# VPAC0_COMMON_0_PAR_VPAC_VISS0_S_VBUSP_VISS_RAWFE_CFG_MMR_S_VBUSP_RAWFE_CFG register map
Vendor: Texas Instruments
Peripheral module from a debugger description file (folder J721S2).
Registers are 32-bit, read-write, reset 0x0 unless marked. A register's access mark holds for its fields unless they carry their own. Offsets are as the file gives them; lines under a group give offsets from that group; [hi:lo] are bit positions; {n}, {i} and the like mark numbered series; 'fields as' and 'values as' point back to an identical list; <NAME> marks a mode.

## VPAC0_COMMON_0_PAR_VPAC_VISS0_S_VBUSP_VISS_RAWFE_CFG_MMR_S_VBUSP_RAWFE_CFG
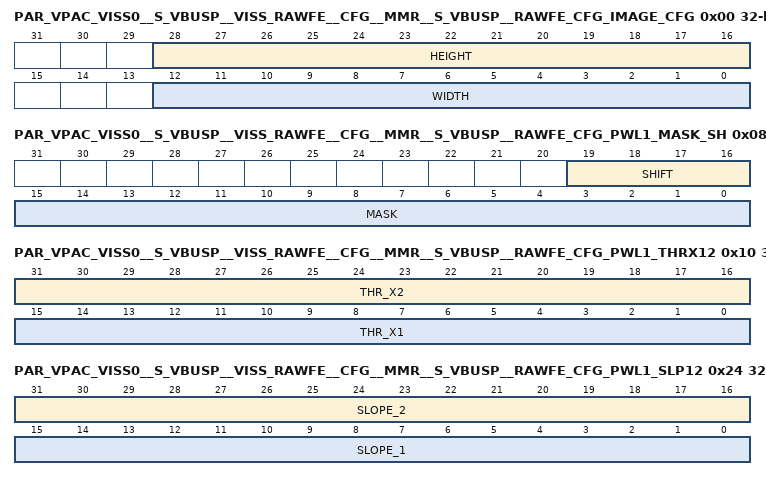
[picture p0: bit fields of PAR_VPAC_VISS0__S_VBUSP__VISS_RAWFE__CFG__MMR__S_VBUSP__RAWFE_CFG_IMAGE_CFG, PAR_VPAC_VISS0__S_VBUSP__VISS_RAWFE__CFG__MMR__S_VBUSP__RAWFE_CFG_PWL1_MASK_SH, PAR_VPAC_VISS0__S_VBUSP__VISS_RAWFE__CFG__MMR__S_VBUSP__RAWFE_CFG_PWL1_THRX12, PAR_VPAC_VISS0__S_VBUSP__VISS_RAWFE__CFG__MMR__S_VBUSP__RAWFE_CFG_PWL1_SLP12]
0x00 PAR_VPAC_VISS0__S_VBUSP__VISS_RAWFE__CFG__MMR__S_VBUSP__RAWFE_CFG_IMAGE_CFG
  [28:16] HEIGHT — image height
  [12:0] WIDTH — image width
0x04 PAR_VPAC_VISS0__S_VBUSP__VISS_RAWFE__CFG__MMR__S_VBUSP__RAWFE_CFG_SHADOW_CFG
  [0] LUT3_SHDW_EN — use LUT2 ram as LUT table for LUT3 processing
0x08 PAR_VPAC_VISS0__S_VBUSP__VISS_RAWFE__CFG__MMR__S_VBUSP__RAWFE_CFG_PWL1_MASK_SH
  [19:16] SHIFT — number of right shift
  [15:0] MASK — mask bit pattern
0x0C PAR_VPAC_VISS0__S_VBUSP__VISS_RAWFE__CFG__MMR__S_VBUSP__RAWFE_CFG_PWL1_EN
  [0] ENABLE
0x10 PAR_VPAC_VISS0__S_VBUSP__VISS_RAWFE__CFG__MMR__S_VBUSP__RAWFE_CFG_PWL1_THRX12
  [31:16] THR_X2 — threshold X2
  [15:0] THR_X1 — threshold X1
0x14 PAR_VPAC_VISS0__S_VBUSP__VISS_RAWFE__CFG__MMR__S_VBUSP__RAWFE_CFG_PWL1_THRX3
  [15:0] THR_X3 — threshold X3
{0x14+4i} PAR_VPAC_VISS0__S_VBUSP__VISS_RAWFE__CFG__MMR__S_VBUSP__RAWFE_CFG_PWL1_THRY{i} (i=1..3)
  [23:0] THR_Y{i} — threshold Y{i}
0x24 PAR_VPAC_VISS0__S_VBUSP__VISS_RAWFE__CFG__MMR__S_VBUSP__RAWFE_CFG_PWL1_SLP12
  [31:16] SLOPE_2, [15:0] SLOPE_1
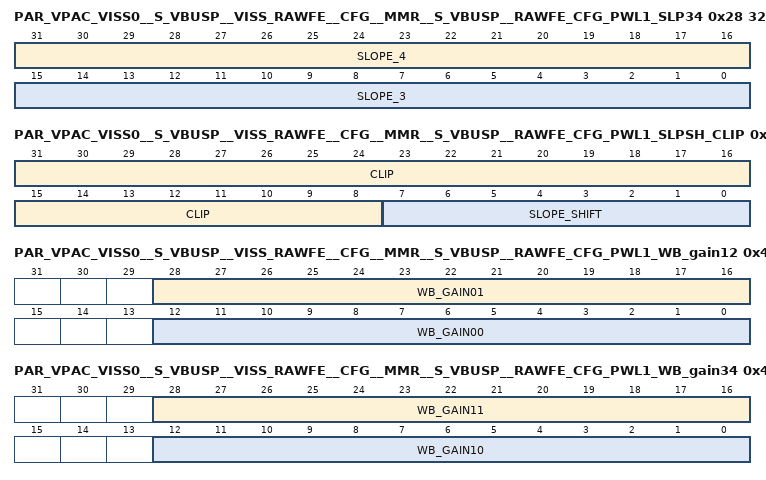
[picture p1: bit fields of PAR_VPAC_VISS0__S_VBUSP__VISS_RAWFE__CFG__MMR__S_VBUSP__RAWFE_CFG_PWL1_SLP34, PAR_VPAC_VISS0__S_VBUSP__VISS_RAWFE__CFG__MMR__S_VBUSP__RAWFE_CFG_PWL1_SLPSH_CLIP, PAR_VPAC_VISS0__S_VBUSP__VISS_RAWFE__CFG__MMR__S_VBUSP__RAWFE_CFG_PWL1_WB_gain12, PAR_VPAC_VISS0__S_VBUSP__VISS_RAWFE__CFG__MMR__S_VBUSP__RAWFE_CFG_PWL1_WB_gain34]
0x28 PAR_VPAC_VISS0__S_VBUSP__VISS_RAWFE__CFG__MMR__S_VBUSP__RAWFE_CFG_PWL1_SLP34
  [31:16] SLOPE_4, [15:0] SLOPE_3
0x2C PAR_VPAC_VISS0__S_VBUSP__VISS_RAWFE__CFG__MMR__S_VBUSP__RAWFE_CFG_PWL1_SLPSH_CLIP
  [31:8] CLIP — clip value
  [7:0] SLOPE_SHIFT — shift value for slope, must not exceed decimal 33.
0x30 PAR_VPAC_VISS0__S_VBUSP__VISS_RAWFE__CFG__MMR__S_VBUSP__RAWFE_CFG_PWL1_OFF1 access not given
  [23:0] OFST00 rw — S24, Offset at pixel 00
0x34 PAR_VPAC_VISS0__S_VBUSP__VISS_RAWFE__CFG__MMR__S_VBUSP__RAWFE_CFG_PWL1_OFF2 access not given
  [23:0] OFST01 rw — S24, Offset at pixel 01
0x38 PAR_VPAC_VISS0__S_VBUSP__VISS_RAWFE__CFG__MMR__S_VBUSP__RAWFE_CFG_PWL1_OFF3 access not given
  [23:0] OFST10 rw — S24, Offset at pixel 10
0x3C PAR_VPAC_VISS0__S_VBUSP__VISS_RAWFE__CFG__MMR__S_VBUSP__RAWFE_CFG_PWL1_OFF4 access not given
  [23:0] OFST11 rw — S24, Offset at pixel 11
0x40 PAR_VPAC_VISS0__S_VBUSP__VISS_RAWFE__CFG__MMR__S_VBUSP__RAWFE_CFG_PWL1_WB_gain12
  [28:16] WB_GAIN01 — U13Q9, WB gain at pixel 01
  [12:0] WB_GAIN00 — U13Q9, WB gain at pixel 00
0x44 PAR_VPAC_VISS0__S_VBUSP__VISS_RAWFE__CFG__MMR__S_VBUSP__RAWFE_CFG_PWL1_WB_gain34
  [28:16] WB_GAIN11 — U13Q9, WB gain at pixel 11
  [12:0] WB_GAIN10 — U13Q9, WB gain at pixel 10
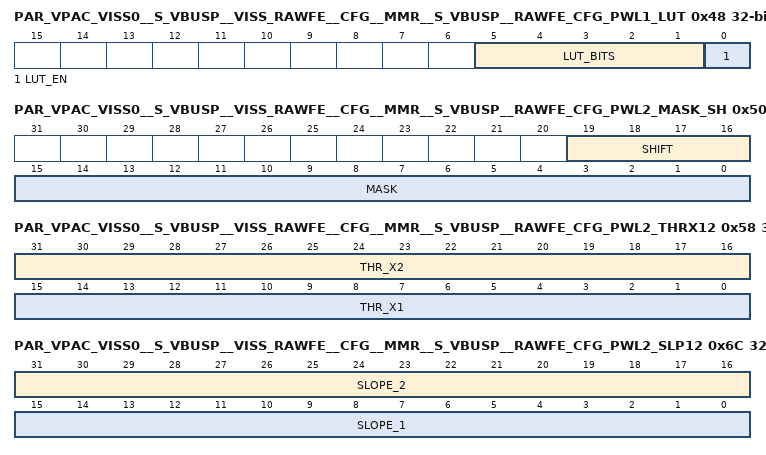
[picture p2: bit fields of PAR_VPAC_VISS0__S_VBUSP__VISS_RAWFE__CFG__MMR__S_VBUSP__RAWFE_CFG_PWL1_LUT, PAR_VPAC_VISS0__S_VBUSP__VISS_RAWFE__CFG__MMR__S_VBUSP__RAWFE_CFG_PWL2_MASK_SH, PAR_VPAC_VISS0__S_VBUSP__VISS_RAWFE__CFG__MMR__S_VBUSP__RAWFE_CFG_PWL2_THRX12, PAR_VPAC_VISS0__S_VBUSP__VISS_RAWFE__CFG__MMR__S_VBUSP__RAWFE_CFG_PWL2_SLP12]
0x48 PAR_VPAC_VISS0__S_VBUSP__VISS_RAWFE__CFG__MMR__S_VBUSP__RAWFE_CFG_PWL1_LUT
  [5:1] LUT_BITS — LUT input bit depth, up to 24
  [0] LUT_EN — enable LUT based compression
0x4C PAR_VPAC_VISS0__S_VBUSP__VISS_RAWFE__CFG__MMR__S_VBUSP__RAWFE_CFG_PWL1_LUTCLIP
  [15:0] LUTCLIP — LUT clip value
0x50 PAR_VPAC_VISS0__S_VBUSP__VISS_RAWFE__CFG__MMR__S_VBUSP__RAWFE_CFG_PWL2_MASK_SH
  fields as PAR_VPAC_VISS0__S_VBUSP__VISS_RAWFE__CFG__MMR__S_VBUSP__RAWFE_CFG_PWL1_MASK_SH
0x54 PAR_VPAC_VISS0__S_VBUSP__VISS_RAWFE__CFG__MMR__S_VBUSP__RAWFE_CFG_PWL2_EN
  [0] ENABLE
0x58 PAR_VPAC_VISS0__S_VBUSP__VISS_RAWFE__CFG__MMR__S_VBUSP__RAWFE_CFG_PWL2_THRX12
  [31:16] THR_X2 — threshold X2
  [15:0] THR_X1 — threshold X1
0x5C PAR_VPAC_VISS0__S_VBUSP__VISS_RAWFE__CFG__MMR__S_VBUSP__RAWFE_CFG_PWL2_THRX3
  [15:0] THR_X3 — threshold X3
{0x5C+4i} PAR_VPAC_VISS0__S_VBUSP__VISS_RAWFE__CFG__MMR__S_VBUSP__RAWFE_CFG_PWL2_THRY{i} (i=1..3)
  [23:0] THR_Y{i} — threshold Y{i}
0x6C PAR_VPAC_VISS0__S_VBUSP__VISS_RAWFE__CFG__MMR__S_VBUSP__RAWFE_CFG_PWL2_SLP12
  [31:16] SLOPE_2, [15:0] SLOPE_1
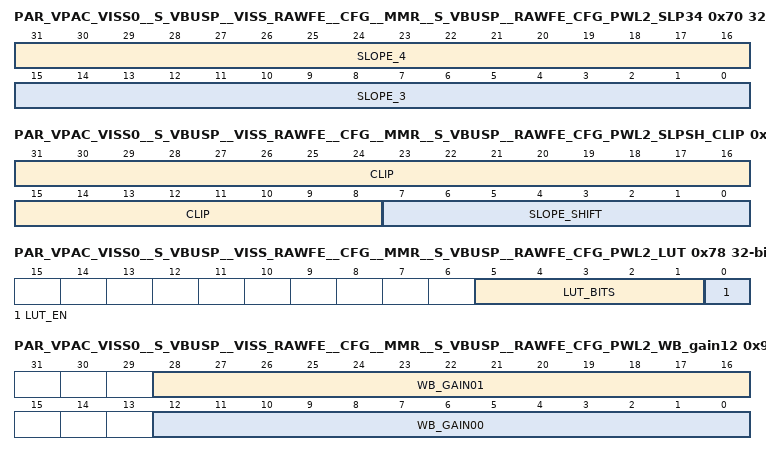
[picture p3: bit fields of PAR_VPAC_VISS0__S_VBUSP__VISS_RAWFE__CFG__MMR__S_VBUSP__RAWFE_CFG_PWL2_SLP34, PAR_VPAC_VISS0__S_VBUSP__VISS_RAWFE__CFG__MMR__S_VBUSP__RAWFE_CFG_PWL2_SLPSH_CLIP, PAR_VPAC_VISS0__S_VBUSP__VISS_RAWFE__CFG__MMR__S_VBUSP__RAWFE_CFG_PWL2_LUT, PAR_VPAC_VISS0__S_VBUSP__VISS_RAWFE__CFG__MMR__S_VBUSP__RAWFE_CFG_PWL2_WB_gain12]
0x70 PAR_VPAC_VISS0__S_VBUSP__VISS_RAWFE__CFG__MMR__S_VBUSP__RAWFE_CFG_PWL2_SLP34
  [31:16] SLOPE_4, [15:0] SLOPE_3
0x74 PAR_VPAC_VISS0__S_VBUSP__VISS_RAWFE__CFG__MMR__S_VBUSP__RAWFE_CFG_PWL2_SLPSH_CLIP
  [31:8] CLIP — clip value
  [7:0] SLOPE_SHIFT — shift value for slope, must not exceed decimal 33
0x78 PAR_VPAC_VISS0__S_VBUSP__VISS_RAWFE__CFG__MMR__S_VBUSP__RAWFE_CFG_PWL2_LUT
  fields as PAR_VPAC_VISS0__S_VBUSP__VISS_RAWFE__CFG__MMR__S_VBUSP__RAWFE_CFG_PWL1_LUT
0x7C PAR_VPAC_VISS0__S_VBUSP__VISS_RAWFE__CFG__MMR__S_VBUSP__RAWFE_CFG_PWL2_LUTCLIP
  [15:0] LUTCLIP — LUT clip value
0x80 PAR_VPAC_VISS0__S_VBUSP__VISS_RAWFE__CFG__MMR__S_VBUSP__RAWFE_CFG_PWL2_OFF1 access not given
  [23:0] OFST00 rw — S24, WB Offset at pixel 00
0x84 PAR_VPAC_VISS0__S_VBUSP__VISS_RAWFE__CFG__MMR__S_VBUSP__RAWFE_CFG_PWL2_OFF2 access not given
  [23:0] OFST01 rw — S24, Offset at pixel 01
0x88 PAR_VPAC_VISS0__S_VBUSP__VISS_RAWFE__CFG__MMR__S_VBUSP__RAWFE_CFG_PWL2_OFF3 access not given
  [23:0] OFST10 rw — S24, Offset at pixel 10
0x8C PAR_VPAC_VISS0__S_VBUSP__VISS_RAWFE__CFG__MMR__S_VBUSP__RAWFE_CFG_PWL2_OFF4 access not given
  [23:0] OFST11 rw — S24, Offset at pixel 11
0x90 PAR_VPAC_VISS0__S_VBUSP__VISS_RAWFE__CFG__MMR__S_VBUSP__RAWFE_CFG_PWL2_WB_gain12
  fields as PAR_VPAC_VISS0__S_VBUSP__VISS_RAWFE__CFG__MMR__S_VBUSP__RAWFE_CFG_PWL1_WB_gain12
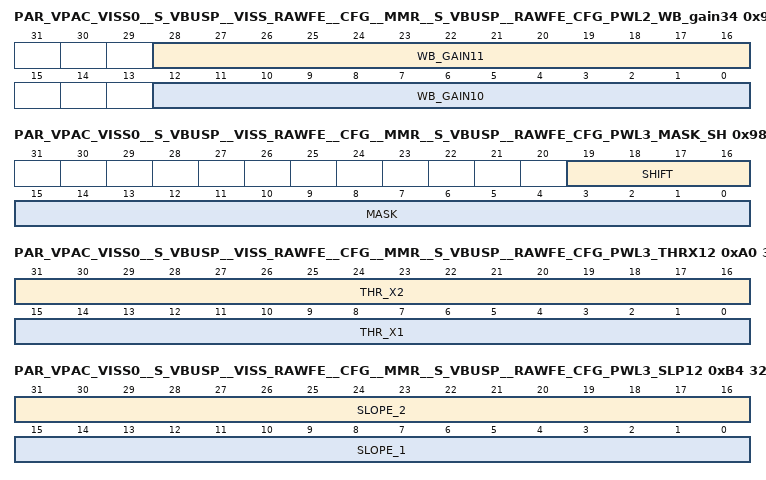
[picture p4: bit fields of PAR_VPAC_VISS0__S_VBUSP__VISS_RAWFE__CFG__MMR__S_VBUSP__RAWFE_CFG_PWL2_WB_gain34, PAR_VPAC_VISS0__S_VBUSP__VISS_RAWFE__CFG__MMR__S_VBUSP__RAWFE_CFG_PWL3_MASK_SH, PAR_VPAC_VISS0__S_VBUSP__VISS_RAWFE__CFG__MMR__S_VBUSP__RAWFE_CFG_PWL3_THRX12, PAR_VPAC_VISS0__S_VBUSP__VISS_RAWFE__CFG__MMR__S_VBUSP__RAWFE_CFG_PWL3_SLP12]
0x94 PAR_VPAC_VISS0__S_VBUSP__VISS_RAWFE__CFG__MMR__S_VBUSP__RAWFE_CFG_PWL2_WB_gain34
  fields as PAR_VPAC_VISS0__S_VBUSP__VISS_RAWFE__CFG__MMR__S_VBUSP__RAWFE_CFG_PWL1_WB_gain34
0x98 PAR_VPAC_VISS0__S_VBUSP__VISS_RAWFE__CFG__MMR__S_VBUSP__RAWFE_CFG_PWL3_MASK_SH
  fields as PAR_VPAC_VISS0__S_VBUSP__VISS_RAWFE__CFG__MMR__S_VBUSP__RAWFE_CFG_PWL1_MASK_SH
0x9C PAR_VPAC_VISS0__S_VBUSP__VISS_RAWFE__CFG__MMR__S_VBUSP__RAWFE_CFG_PWL3_EN
  [0] ENABLE
0xA0 PAR_VPAC_VISS0__S_VBUSP__VISS_RAWFE__CFG__MMR__S_VBUSP__RAWFE_CFG_PWL3_THRX12
  [31:16] THR_X2 — threshold X2
  [15:0] THR_X1 — threshold X1
0xA4 PAR_VPAC_VISS0__S_VBUSP__VISS_RAWFE__CFG__MMR__S_VBUSP__RAWFE_CFG_PWL3_THRX3
  [15:0] THR_X3 — threshold X3
{0xA4+4i} PAR_VPAC_VISS0__S_VBUSP__VISS_RAWFE__CFG__MMR__S_VBUSP__RAWFE_CFG_PWL3_THRY{i} (i=1..3)
  [23:0] THR_Y{i} — threshold Y{i}
0xB4 PAR_VPAC_VISS0__S_VBUSP__VISS_RAWFE__CFG__MMR__S_VBUSP__RAWFE_CFG_PWL3_SLP12
  [31:16] SLOPE_2, [15:0] SLOPE_1
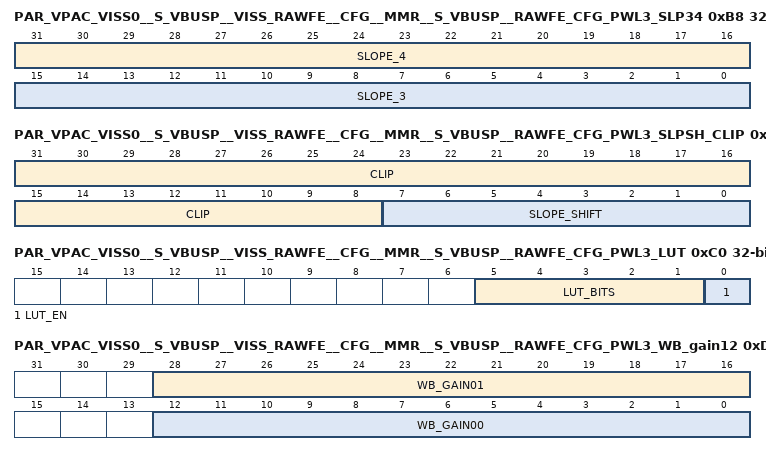
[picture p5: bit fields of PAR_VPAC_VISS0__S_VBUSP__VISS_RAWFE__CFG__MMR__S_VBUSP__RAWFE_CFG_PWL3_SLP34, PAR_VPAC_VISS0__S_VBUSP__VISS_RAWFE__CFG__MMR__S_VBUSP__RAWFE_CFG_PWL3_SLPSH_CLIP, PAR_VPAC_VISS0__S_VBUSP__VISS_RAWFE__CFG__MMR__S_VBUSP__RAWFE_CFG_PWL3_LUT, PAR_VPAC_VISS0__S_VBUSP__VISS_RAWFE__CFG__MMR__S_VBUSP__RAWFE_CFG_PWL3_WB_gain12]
0xB8 PAR_VPAC_VISS0__S_VBUSP__VISS_RAWFE__CFG__MMR__S_VBUSP__RAWFE_CFG_PWL3_SLP34
  [31:16] SLOPE_4, [15:0] SLOPE_3
0xBC PAR_VPAC_VISS0__S_VBUSP__VISS_RAWFE__CFG__MMR__S_VBUSP__RAWFE_CFG_PWL3_SLPSH_CLIP
  fields as PAR_VPAC_VISS0__S_VBUSP__VISS_RAWFE__CFG__MMR__S_VBUSP__RAWFE_CFG_PWL2_SLPSH_CLIP
0xC0 PAR_VPAC_VISS0__S_VBUSP__VISS_RAWFE__CFG__MMR__S_VBUSP__RAWFE_CFG_PWL3_LUT
  fields as PAR_VPAC_VISS0__S_VBUSP__VISS_RAWFE__CFG__MMR__S_VBUSP__RAWFE_CFG_PWL1_LUT
0xC4 PAR_VPAC_VISS0__S_VBUSP__VISS_RAWFE__CFG__MMR__S_VBUSP__RAWFE_CFG_PWL3_LUTCLIP
  [15:0] LUTCLIP — LUT clip value
0xC8 PAR_VPAC_VISS0__S_VBUSP__VISS_RAWFE__CFG__MMR__S_VBUSP__RAWFE_CFG_PWL3_OFF1 access not given
  [23:0] OFST00 rw — S24, Offset at pixel 00
0xCC PAR_VPAC_VISS0__S_VBUSP__VISS_RAWFE__CFG__MMR__S_VBUSP__RAWFE_CFG_PWL3_OFF2 access not given
  [23:0] OFST01 rw — S24, Offset at pixel 01
0xD0 PAR_VPAC_VISS0__S_VBUSP__VISS_RAWFE__CFG__MMR__S_VBUSP__RAWFE_CFG_PWL3_OFF3 access not given
  [23:0] OFST10 rw — S24, Offset at pixel 10
0xD4 PAR_VPAC_VISS0__S_VBUSP__VISS_RAWFE__CFG__MMR__S_VBUSP__RAWFE_CFG_PWL3_OFF4 access not given
  [23:0] OFST11 rw — S24, Offset at pixel 11
0xD8 PAR_VPAC_VISS0__S_VBUSP__VISS_RAWFE__CFG__MMR__S_VBUSP__RAWFE_CFG_PWL3_WB_gain12
  fields as PAR_VPAC_VISS0__S_VBUSP__VISS_RAWFE__CFG__MMR__S_VBUSP__RAWFE_CFG_PWL1_WB_gain12
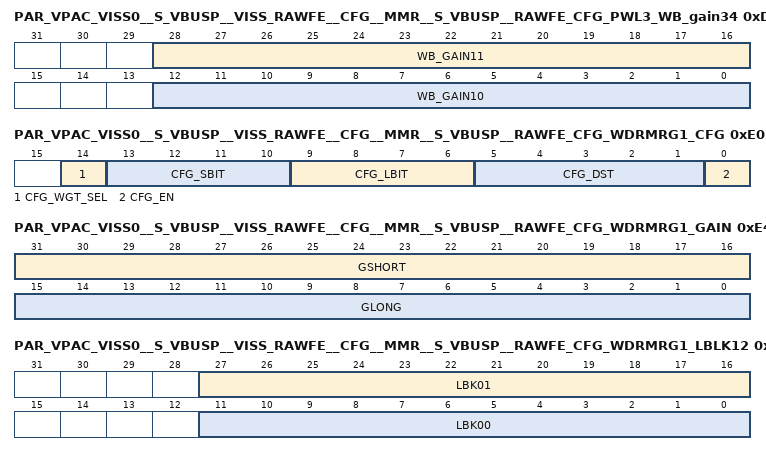
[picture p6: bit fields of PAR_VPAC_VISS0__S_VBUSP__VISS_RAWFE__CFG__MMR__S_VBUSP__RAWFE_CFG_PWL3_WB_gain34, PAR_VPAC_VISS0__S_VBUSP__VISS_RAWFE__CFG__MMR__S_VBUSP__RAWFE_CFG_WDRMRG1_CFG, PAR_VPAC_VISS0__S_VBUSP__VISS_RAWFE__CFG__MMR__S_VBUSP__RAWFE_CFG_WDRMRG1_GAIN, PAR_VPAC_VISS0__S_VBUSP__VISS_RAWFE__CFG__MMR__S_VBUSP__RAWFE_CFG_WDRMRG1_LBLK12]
0xDC PAR_VPAC_VISS0__S_VBUSP__VISS_RAWFE__CFG__MMR__S_VBUSP__RAWFE_CFG_PWL3_WB_gain34
  fields as PAR_VPAC_VISS0__S_VBUSP__VISS_RAWFE__CFG__MMR__S_VBUSP__RAWFE_CFG_PWL1_WB_gain34
0xE0 PAR_VPAC_VISS0__S_VBUSP__VISS_RAWFE__CFG__MMR__S_VBUSP__RAWFE_CFG_WDRMRG1_CFG
  [14] CFG_WGT_SEL — Select source for weight calculation (0:long, 1: short)
  [13:10] CFG_SBIT — U4, short exposure image bit shift
  [9:6] CFG_LBIT — U4, long exposure image bit shift
  [5:1] CFG_DST — U5, down shift value after WDR merge
  [0] CFG_EN — enable
0xE4 PAR_VPAC_VISS0__S_VBUSP__VISS_RAWFE__CFG__MMR__S_VBUSP__RAWFE_CFG_WDRMRG1_GAIN
  [31:16] GSHORT — U16Q15, gain for long frame
  [15:0] GLONG — U16Q15, gain for short frame
0xE8 PAR_VPAC_VISS0__S_VBUSP__VISS_RAWFE__CFG__MMR__S_VBUSP__RAWFE_CFG_WDRMRG1_LBLK12
  [27:16] LBK01 — U12, black level for long frame at pixel 01
  [11:0] LBK00 — U12, black level for long frame at pixel 00
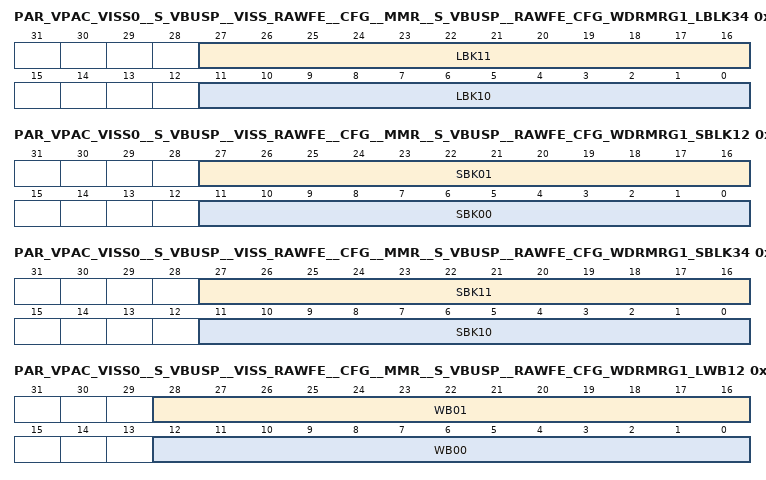
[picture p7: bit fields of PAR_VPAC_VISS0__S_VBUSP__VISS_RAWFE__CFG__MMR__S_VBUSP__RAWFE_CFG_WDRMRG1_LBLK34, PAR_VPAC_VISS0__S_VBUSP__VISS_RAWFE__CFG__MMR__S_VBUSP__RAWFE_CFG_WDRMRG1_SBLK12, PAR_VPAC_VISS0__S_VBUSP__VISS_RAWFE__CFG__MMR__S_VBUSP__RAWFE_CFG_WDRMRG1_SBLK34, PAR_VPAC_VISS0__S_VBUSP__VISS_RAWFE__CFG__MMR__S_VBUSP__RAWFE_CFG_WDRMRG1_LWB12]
0xEC PAR_VPAC_VISS0__S_VBUSP__VISS_RAWFE__CFG__MMR__S_VBUSP__RAWFE_CFG_WDRMRG1_LBLK34
  [27:16] LBK11 — U12, black level for long frame at pixel 11
  [11:0] LBK10 — U12, black level for long frame at pixel 10
0xF0 PAR_VPAC_VISS0__S_VBUSP__VISS_RAWFE__CFG__MMR__S_VBUSP__RAWFE_CFG_WDRMRG1_SBLK12
  [27:16] SBK01 — U12, black level for short frame at pixel 01
  [11:0] SBK00 — U12, black level for short frame at pixel 00
0xF4 PAR_VPAC_VISS0__S_VBUSP__VISS_RAWFE__CFG__MMR__S_VBUSP__RAWFE_CFG_WDRMRG1_SBLK34
  [27:16] SBK11 — U12, black level for short frame at pixel 11
  [11:0] SBK10 — U12, black level for short frame at pixel 10
0xF8 PAR_VPAC_VISS0__S_VBUSP__VISS_RAWFE__CFG__MMR__S_VBUSP__RAWFE_CFG_WDRMRG1_LWB12
  [28:16] WB01 — U13Q9, WB gain for long frame at pixel 01
  [12:0] WB00 — U13Q9, WB gain for long frame at pixel 00
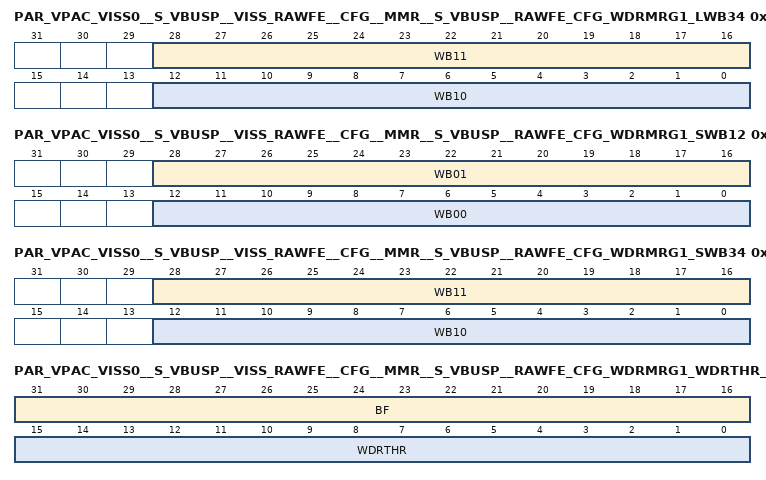
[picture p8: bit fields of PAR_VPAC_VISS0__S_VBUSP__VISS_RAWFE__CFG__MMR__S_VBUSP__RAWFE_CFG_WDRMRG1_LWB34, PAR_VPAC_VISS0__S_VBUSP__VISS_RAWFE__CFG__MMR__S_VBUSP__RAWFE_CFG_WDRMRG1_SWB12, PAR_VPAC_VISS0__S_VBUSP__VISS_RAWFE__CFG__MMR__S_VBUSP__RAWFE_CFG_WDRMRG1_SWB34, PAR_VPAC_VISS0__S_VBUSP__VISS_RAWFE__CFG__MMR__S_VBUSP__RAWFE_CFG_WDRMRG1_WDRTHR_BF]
0xFC PAR_VPAC_VISS0__S_VBUSP__VISS_RAWFE__CFG__MMR__S_VBUSP__RAWFE_CFG_WDRMRG1_LWB34
  [28:16] WB11 — U13Q9, WB gain for long frame at pixel 11
  [12:0] WB10 — U13Q9, WB gain for long frame at pixel 10
0x100 PAR_VPAC_VISS0__S_VBUSP__VISS_RAWFE__CFG__MMR__S_VBUSP__RAWFE_CFG_WDRMRG1_SWB12
  [28:16] WB01 — U13Q9, WB gain for short frame at pixel 01
  [12:0] WB00 — U13Q9, WB gain for short frame at pixel 00
0x104 PAR_VPAC_VISS0__S_VBUSP__VISS_RAWFE__CFG__MMR__S_VBUSP__RAWFE_CFG_WDRMRG1_SWB34
  [28:16] WB11 — U13Q9, WB gain for short frame at pixel 11
  [12:0] WB10 — U13Q9, WB gain for short frame at pixel 10
0x108 PAR_VPAC_VISS0__S_VBUSP__VISS_RAWFE__CFG__MMR__S_VBUSP__RAWFE_CFG_WDRMRG1_WDRTHR_BF
  [31:16] BF — S16, bf parameter for merge
  [15:0] WDRTHR — U16, WDR threshold for merge
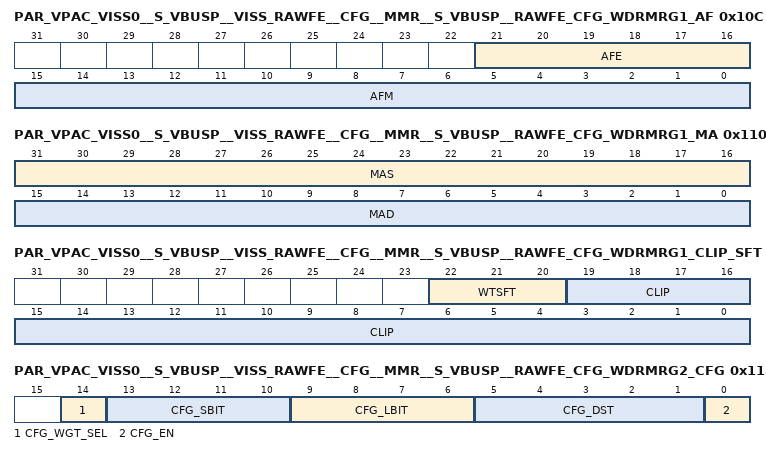
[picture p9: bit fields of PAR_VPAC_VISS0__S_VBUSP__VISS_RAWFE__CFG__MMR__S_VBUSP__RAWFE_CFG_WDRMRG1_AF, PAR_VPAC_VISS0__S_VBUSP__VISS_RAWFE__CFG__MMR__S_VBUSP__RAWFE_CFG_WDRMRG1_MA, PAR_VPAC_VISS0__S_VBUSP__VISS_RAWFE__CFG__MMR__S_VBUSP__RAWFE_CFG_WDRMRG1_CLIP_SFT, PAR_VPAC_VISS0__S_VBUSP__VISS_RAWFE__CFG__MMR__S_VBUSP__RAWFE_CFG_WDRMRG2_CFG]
0x10C PAR_VPAC_VISS0__S_VBUSP__VISS_RAWFE__CFG__MMR__S_VBUSP__RAWFE_CFG_WDRMRG1_AF
  [21:16] AFE — U6, af_e parameter for merge
  [15:0] AFM — S16, af_m parameter for merge
0x110 PAR_VPAC_VISS0__S_VBUSP__VISS_RAWFE__CFG__MMR__S_VBUSP__RAWFE_CFG_WDRMRG1_MA
  [31:16] MAS — U16, slope for merge MA filter
  [15:0] MAD — U16, lower threshold for merge MA filter
0x114 PAR_VPAC_VISS0__S_VBUSP__VISS_RAWFE__CFG__MMR__S_VBUSP__RAWFE_CFG_WDRMRG1_CLIP_SFT
  [22:20] WTSFT — U3, shift before weight block
  [19:0] CLIP — U20, output clip value. It is a software restriction to always ensure that the clipped value is a 16-bit number for first wdr stage.
0x118 PAR_VPAC_VISS0__S_VBUSP__VISS_RAWFE__CFG__MMR__S_VBUSP__RAWFE_CFG_WDRMRG2_CFG
  fields as PAR_VPAC_VISS0__S_VBUSP__VISS_RAWFE__CFG__MMR__S_VBUSP__RAWFE_CFG_WDRMRG1_CFG
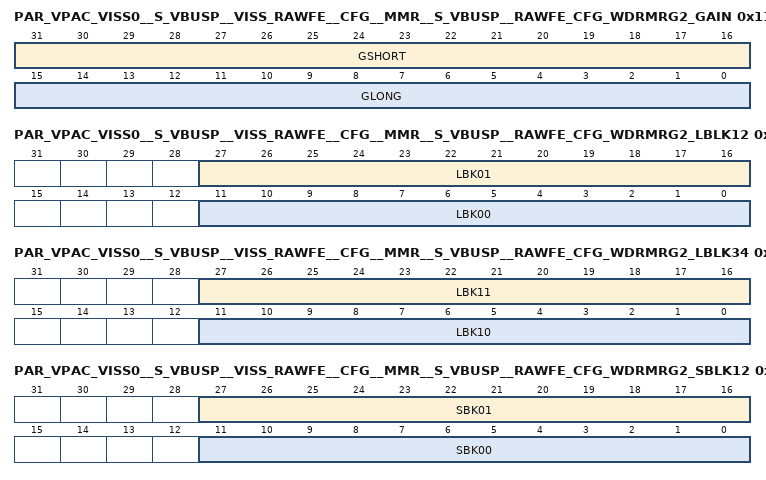
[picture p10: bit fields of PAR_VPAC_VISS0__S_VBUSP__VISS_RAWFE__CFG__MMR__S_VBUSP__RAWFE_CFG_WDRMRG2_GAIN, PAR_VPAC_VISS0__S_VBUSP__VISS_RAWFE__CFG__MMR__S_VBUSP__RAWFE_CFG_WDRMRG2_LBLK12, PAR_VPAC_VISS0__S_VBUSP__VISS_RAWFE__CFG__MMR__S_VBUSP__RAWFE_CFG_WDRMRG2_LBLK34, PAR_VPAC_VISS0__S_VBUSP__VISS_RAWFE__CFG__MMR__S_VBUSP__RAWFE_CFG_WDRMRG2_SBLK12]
0x11C PAR_VPAC_VISS0__S_VBUSP__VISS_RAWFE__CFG__MMR__S_VBUSP__RAWFE_CFG_WDRMRG2_GAIN
  fields as PAR_VPAC_VISS0__S_VBUSP__VISS_RAWFE__CFG__MMR__S_VBUSP__RAWFE_CFG_WDRMRG1_GAIN
0x120 PAR_VPAC_VISS0__S_VBUSP__VISS_RAWFE__CFG__MMR__S_VBUSP__RAWFE_CFG_WDRMRG2_LBLK12
  fields as PAR_VPAC_VISS0__S_VBUSP__VISS_RAWFE__CFG__MMR__S_VBUSP__RAWFE_CFG_WDRMRG1_LBLK12
0x124 PAR_VPAC_VISS0__S_VBUSP__VISS_RAWFE__CFG__MMR__S_VBUSP__RAWFE_CFG_WDRMRG2_LBLK34
  fields as PAR_VPAC_VISS0__S_VBUSP__VISS_RAWFE__CFG__MMR__S_VBUSP__RAWFE_CFG_WDRMRG1_LBLK34
0x128 PAR_VPAC_VISS0__S_VBUSP__VISS_RAWFE__CFG__MMR__S_VBUSP__RAWFE_CFG_WDRMRG2_SBLK12
  fields as PAR_VPAC_VISS0__S_VBUSP__VISS_RAWFE__CFG__MMR__S_VBUSP__RAWFE_CFG_WDRMRG1_SBLK12
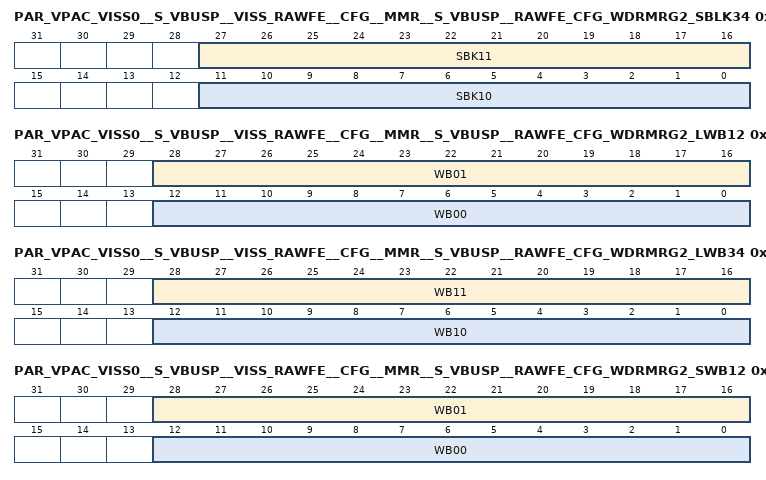
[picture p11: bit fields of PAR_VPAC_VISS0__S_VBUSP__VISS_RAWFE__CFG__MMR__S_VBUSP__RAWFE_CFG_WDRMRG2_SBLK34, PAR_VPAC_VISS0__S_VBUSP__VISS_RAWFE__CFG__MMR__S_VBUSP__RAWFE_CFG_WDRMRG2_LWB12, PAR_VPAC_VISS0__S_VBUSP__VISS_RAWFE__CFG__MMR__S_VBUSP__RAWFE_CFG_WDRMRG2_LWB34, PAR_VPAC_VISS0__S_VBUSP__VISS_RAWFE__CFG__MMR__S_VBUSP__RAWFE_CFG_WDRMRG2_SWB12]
0x12C PAR_VPAC_VISS0__S_VBUSP__VISS_RAWFE__CFG__MMR__S_VBUSP__RAWFE_CFG_WDRMRG2_SBLK34
  fields as PAR_VPAC_VISS0__S_VBUSP__VISS_RAWFE__CFG__MMR__S_VBUSP__RAWFE_CFG_WDRMRG1_SBLK34
0x130 PAR_VPAC_VISS0__S_VBUSP__VISS_RAWFE__CFG__MMR__S_VBUSP__RAWFE_CFG_WDRMRG2_LWB12
  fields as PAR_VPAC_VISS0__S_VBUSP__VISS_RAWFE__CFG__MMR__S_VBUSP__RAWFE_CFG_WDRMRG1_LWB12
0x134 PAR_VPAC_VISS0__S_VBUSP__VISS_RAWFE__CFG__MMR__S_VBUSP__RAWFE_CFG_WDRMRG2_LWB34
  fields as PAR_VPAC_VISS0__S_VBUSP__VISS_RAWFE__CFG__MMR__S_VBUSP__RAWFE_CFG_WDRMRG1_LWB34
0x138 PAR_VPAC_VISS0__S_VBUSP__VISS_RAWFE__CFG__MMR__S_VBUSP__RAWFE_CFG_WDRMRG2_SWB12
  fields as PAR_VPAC_VISS0__S_VBUSP__VISS_RAWFE__CFG__MMR__S_VBUSP__RAWFE_CFG_WDRMRG1_SWB12
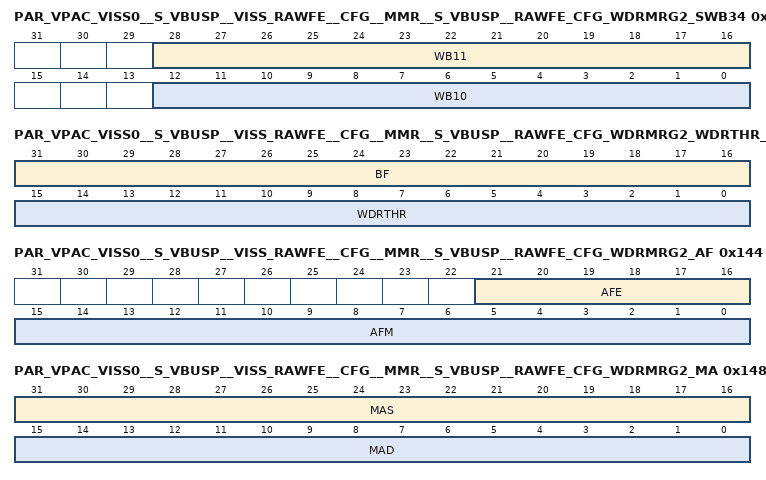
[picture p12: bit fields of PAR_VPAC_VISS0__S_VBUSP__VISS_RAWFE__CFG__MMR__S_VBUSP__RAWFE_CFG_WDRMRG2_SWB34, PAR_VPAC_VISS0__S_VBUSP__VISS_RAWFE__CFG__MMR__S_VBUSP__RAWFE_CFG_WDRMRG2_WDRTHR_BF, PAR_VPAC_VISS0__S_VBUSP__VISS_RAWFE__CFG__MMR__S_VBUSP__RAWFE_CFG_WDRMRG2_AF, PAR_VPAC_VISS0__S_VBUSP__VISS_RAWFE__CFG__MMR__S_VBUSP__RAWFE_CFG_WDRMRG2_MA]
0x13C PAR_VPAC_VISS0__S_VBUSP__VISS_RAWFE__CFG__MMR__S_VBUSP__RAWFE_CFG_WDRMRG2_SWB34
  fields as PAR_VPAC_VISS0__S_VBUSP__VISS_RAWFE__CFG__MMR__S_VBUSP__RAWFE_CFG_WDRMRG1_SWB34
0x140 PAR_VPAC_VISS0__S_VBUSP__VISS_RAWFE__CFG__MMR__S_VBUSP__RAWFE_CFG_WDRMRG2_WDRTHR_BF
  fields as PAR_VPAC_VISS0__S_VBUSP__VISS_RAWFE__CFG__MMR__S_VBUSP__RAWFE_CFG_WDRMRG1_WDRTHR_BF
0x144 PAR_VPAC_VISS0__S_VBUSP__VISS_RAWFE__CFG__MMR__S_VBUSP__RAWFE_CFG_WDRMRG2_AF
  fields as PAR_VPAC_VISS0__S_VBUSP__VISS_RAWFE__CFG__MMR__S_VBUSP__RAWFE_CFG_WDRMRG1_AF
0x148 PAR_VPAC_VISS0__S_VBUSP__VISS_RAWFE__CFG__MMR__S_VBUSP__RAWFE_CFG_WDRMRG2_MA
  fields as PAR_VPAC_VISS0__S_VBUSP__VISS_RAWFE__CFG__MMR__S_VBUSP__RAWFE_CFG_WDRMRG1_MA
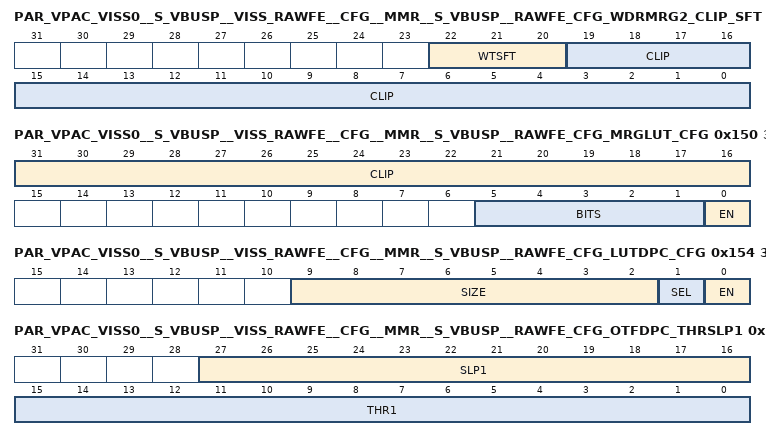
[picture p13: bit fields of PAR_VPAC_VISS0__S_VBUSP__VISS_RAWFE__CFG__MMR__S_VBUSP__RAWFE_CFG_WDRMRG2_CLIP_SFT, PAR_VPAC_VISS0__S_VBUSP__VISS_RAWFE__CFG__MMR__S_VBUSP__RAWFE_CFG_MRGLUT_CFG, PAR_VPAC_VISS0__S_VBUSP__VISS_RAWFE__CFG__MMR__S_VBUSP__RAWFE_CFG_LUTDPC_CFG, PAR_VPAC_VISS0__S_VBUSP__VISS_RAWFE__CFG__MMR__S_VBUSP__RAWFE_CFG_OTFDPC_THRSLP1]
0x14C PAR_VPAC_VISS0__S_VBUSP__VISS_RAWFE__CFG__MMR__S_VBUSP__RAWFE_CFG_WDRMRG2_CLIP_SFT
  [22:20] WTSFT — U3, shift before weight block
  [19:0] CLIP — U20, output clip value
0x150 PAR_VPAC_VISS0__S_VBUSP__VISS_RAWFE__CFG__MMR__S_VBUSP__RAWFE_CFG_MRGLUT_CFG
  [31:16] CLIP — U16, LUT output clip
  [5:1] BITS — U5, LUT input bit depth, up to 24
  [0] EN — LUT enable
0x154 PAR_VPAC_VISS0__S_VBUSP__VISS_RAWFE__CFG__MMR__S_VBUSP__RAWFE_CFG_LUTDPC_CFG
  [9:2] SIZE — U8, number of LUT entires - 1
  [1] SEL — replace with black (0) or whithe (1)
  [0] EN — LUTDPC enable
0x158 PAR_VPAC_VISS0__S_VBUSP__VISS_RAWFE__CFG__MMR__S_VBUSP__RAWFE_CFG_OTFDPC_EN
  [0] EN — OTF DPC enable
{0x158+4i} PAR_VPAC_VISS0__S_VBUSP__VISS_RAWFE__CFG__MMR__S_VBUSP__RAWFE_CFG_OTFDPC_THRSLP{i} (i=1..3)
  [27:16] SLP1 — S12Q8, slope at {512i-512}
  [15:0] THR1 — U16, threshold at {512i-512}
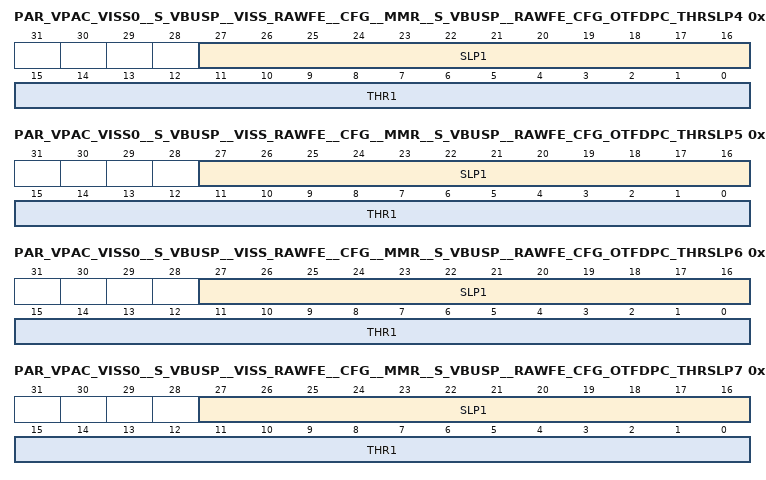
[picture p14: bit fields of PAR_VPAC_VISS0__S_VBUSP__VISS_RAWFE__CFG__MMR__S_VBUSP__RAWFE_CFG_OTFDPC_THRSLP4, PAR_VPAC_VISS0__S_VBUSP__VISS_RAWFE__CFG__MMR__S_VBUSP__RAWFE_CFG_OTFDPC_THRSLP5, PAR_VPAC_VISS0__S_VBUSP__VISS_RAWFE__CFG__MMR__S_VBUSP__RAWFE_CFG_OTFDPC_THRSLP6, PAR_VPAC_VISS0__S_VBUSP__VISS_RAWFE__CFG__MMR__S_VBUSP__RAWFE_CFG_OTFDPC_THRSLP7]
0x168 PAR_VPAC_VISS0__S_VBUSP__VISS_RAWFE__CFG__MMR__S_VBUSP__RAWFE_CFG_OTFDPC_THRSLP4
  [27:16] SLP1 — S12Q8, slope at 2048
  [15:0] THR1 — U16, threshold at 2048
0x16C PAR_VPAC_VISS0__S_VBUSP__VISS_RAWFE__CFG__MMR__S_VBUSP__RAWFE_CFG_OTFDPC_THRSLP5
  [27:16] SLP1 — S12Q8, slope at 4096
  [15:0] THR1 — U16, threshold at 4096
0x170 PAR_VPAC_VISS0__S_VBUSP__VISS_RAWFE__CFG__MMR__S_VBUSP__RAWFE_CFG_OTFDPC_THRSLP6
  [27:16] SLP1 — S12Q8, slope at 8192
  [15:0] THR1 — U16, threshold at 8192
0x174 PAR_VPAC_VISS0__S_VBUSP__VISS_RAWFE__CFG__MMR__S_VBUSP__RAWFE_CFG_OTFDPC_THRSLP7
  [27:16] SLP1 — S12Q8, slope at 16384
  [15:0] THR1 — U16, threshold at 16384
0x178 PAR_VPAC_VISS0__S_VBUSP__VISS_RAWFE__CFG__MMR__S_VBUSP__RAWFE_CFG_OTFDPC_THRSLP8
  [27:16] SLP1 — S12Q8, slope at 32768
  [15:0] THR1 — U16, threshold at 32768
0x17C PAR_VPAC_VISS0__S_VBUSP__VISS_RAWFE__CFG__MMR__S_VBUSP__RAWFE_CFG_LSC_CFG
  [9:7] GAIN_FORMAT — LSC LUT gain format, 0:Q8, 1:Q8+1, 2:Q7, 3:Q7+1, 4:Q6, 5:Q6+1, 6:Q5, 7:Q5+1
  [6:4] MODE_N — vertical LSC LUT downsampling, 3:8x, 4:16x, 5:32x, 6:64x, 7:128x
  [3:1] MODE_M — horizontal LSC LUT downsampling, 3:8x, 4:16x, 5:32x, 6:64x, 7:128x
  [0] EN — LSC enable
0x180 PAR_VPAC_VISS0__S_VBUSP__VISS_RAWFE__CFG__MMR__S_VBUSP__RAWFE_CFG_WB2_offset12
  [31:16] WB_OFST01 — S16, WB offset at pixel 01
  [15:0] WB_OFST00 — S16, WB offset at pixel 00
0x184 PAR_VPAC_VISS0__S_VBUSP__VISS_RAWFE__CFG__MMR__S_VBUSP__RAWFE_CFG_WB2_offset34
  [31:16] WB_OFST11 — S16, WB offset at pixel 11
  [15:0] WB_OFST10 — S16, WB offset at pixel 10
0x188 PAR_VPAC_VISS0__S_VBUSP__VISS_RAWFE__CFG__MMR__S_VBUSP__RAWFE_CFG_WB2_gain12
  fields as PAR_VPAC_VISS0__S_VBUSP__VISS_RAWFE__CFG__MMR__S_VBUSP__RAWFE_CFG_PWL1_WB_gain12
0x18C PAR_VPAC_VISS0__S_VBUSP__VISS_RAWFE__CFG__MMR__S_VBUSP__RAWFE_CFG_WB2_gain34
  fields as PAR_VPAC_VISS0__S_VBUSP__VISS_RAWFE__CFG__MMR__S_VBUSP__RAWFE_CFG_PWL1_WB_gain34
0x190 PAR_VPAC_VISS0__S_VBUSP__VISS_RAWFE__CFG__MMR__S_VBUSP__RAWFE_CFG_H3AMUX_CFG
  [5:2] SHIFT — U8, number of right shift, from 0 to 14
  [1:0] SEL — H3A input selection, 0: long frame, 1: short frame, 2: very short frame, 3: LSC output
0x194 PAR_VPAC_VISS0__S_VBUSP__VISS_RAWFE__CFG__MMR__S_VBUSP__RAWFE_CFG_H3ALUT_CFG
  [25:16] CLIP — U10, LUT output clip value
  [5:1] BITS — U5, LUT input bit depth, up to 24
  [0] EN — LUT enable
0x198 PAR_VPAC_VISS0__S_VBUSP__VISS_RAWFE__CFG__MMR__S_VBUSP__RAWFE_CFG_RAWFE_INT_STAT access not given
  [9] LSC_CFG_ERR — status/clear for lsc config error. This is set when a write or read occurs in the middle of frame processing. This results in data corruption for the frame. write 1 to clear event status, write of 0 has no affect (access R/W1TC)
  [8] DPC_LINE_CFG_ERR — status/clear for dpc line config error. This is set when a write or read occurs in the middle of frame processing. This results in data corruption for the frame. write 1 to clear event status, write of 0 has no affect (access R/W1TC)
  [7] DPC_LUT_CFG_ERR — status/clear for dpc lut configuration error. This is set when a write or read occurs in the middle of frame processing. This results in data corruption for the frame. write 1 to clear event status, write of 0 has no affect (access R/W1TC)
  [6] H3A_ACCM_CFG_ERR — status/clear for h3a accum configuration error. This is set when a write or read occurs in the middle of frame processing. This results in data corruption for the frame. write 1 to clear event status, write of 0 has no affect (access R/W1TC)
  [5] H3A_LINE_CFG_ERR — status/clear for h3a line configuration error. This is set when a write or read occurs in the middle of frame processing. This results in data corruption for the frame. write 1 to clear event status, write of 0 has no affect (access R/W1TC)
  [4] H3A_LUT_CFG_ERR — status/clear for h3a lut configuration error. This is set when a write or read occurs in the middle of frame processing. This results in data corruption for the frame. write 1 to clear event status, write of 0 has no affect (access R/W1TC)
  [3] WDR_LUT_CFG_ERR — status/clear for wdr lut configuration error. This is set when a write or read occurs in the middle of frame processing. This results in data corruption for the frame. write 1 to clear event status, write of 0 has no affect (access R/W1TC)
  [2] LUT3_CFG_ERR — status/clear for lut3 configuration error. This is set when a write or read occurs in the middle of frame processing. This results in data corruption for the frame. write 1 to clear event status, write of 0 has no affect (access R/W1TC)
  [1] LUT2_CFG_ERR — status/clear for lut2 configuration error. This is set when a write or read occurs in the middle of frame processing. This results in data corruption for the frame. write 1 to clear event status, write of 0 has no affect (access R/W1TC)
  [0] LUT1_CFG_ERR — status/clear for lut1 configuration error. This is set when a write or read occurs in the middle of frame processing. This results in data corruption for the frame. write 1 to clear event status, write of 0 has no affect (access R/W1TC)
0x200 PAR_VPAC_VISS0__S_VBUSP__VISS_RAWFE__CFG__MMR__S_VBUSP__RAWFE_CFG_DBG_CTL
  [13:12] DPC_LINE_SEL — select for which dpc line ram to read on debug interface
  [11] PIPE_ADV_EN_EVENT — enable for pixal pipe line advanced
  [10] DPC_OTF_CORR_EN_EVENT — enable for dpc otf corrected a pixel
  [9] LSE_INTF_STALL_EN_EVENT — enable for lse slave port stalled by rawfe
  [8] LSE_MST_STALL_EN_EVENT — enable for lse maaster port stalled on H3A out I/F
  [7] LSE_SLV_STALL_EN_EVENT — enable for lse not sending data in frame on pixel I/F
  [6] HE_EN_EVENT — enable for horizantal end
  [5] HS_EN_EVENT — enable for horizantal start
  [4] VE_EN_EVENT — enable for verticle end
  [3] VS_EN_EVENT — enable for verticle start
  [2] X_Y_EN_EVENT — enable for x,y position match event; Only generates event, no halt
  [1] X_Y_EN_HALT — enable for x,y position match halt; Halts Pipe, clear this bit to resume. Only way to resume is to clear this bit back to 0. You would need to clear the status bit after clearing this bit.
  [0] DBG_EN — Enable debug features, set to '0' to disable all events
0x204 PAR_VPAC_VISS0__S_VBUSP__VISS_RAWFE__CFG__MMR__S_VBUSP__RAWFE_CFG_DBG_HWBP
  [28:16] Y_POS — pixel y position
  [12:0] X_POS — pixel x position
0x208 PAR_VPAC_VISS0__S_VBUSP__VISS_RAWFE__CFG__MMR__S_VBUSP__RAWFE_CFG_DBG_STAT1 access not given
  [11] PIPE_ADV_EVENT — status/clear for pixal pipe line advanced (access R/W1TC)
  [10] DPC_OTF_CORR_EVENT — status/clear for dpc otf corrected a pixel. write 1 to clear event status, write of 0 has no affect (access R/W1TC)
  [9] LSE_INTF_STALL_EVENT — status/clear for lse slave port stalled by rawfe. write 1 to clear event status, write of 0 has no affect (access R/W1TC)
  [8] LSE_MST_STALL_EVENT — status/clear for lse maaster port stalled. write 1 to clear event status, write of 0 has no affect (access R/W1TC)
  [7] LSE_SLV_STALL_EVENT — status/clear for lse not sending data in frame. write 1 to clear event status, write of 0 has no affect (access R/W1TC)
  [6] HE_EVENT — status/clear for horizantal end. write 1 to clear event status, write of 0 has no affect (access R/W1TC)
  [5] HS_EVENT — status/clear for horizantal start. write 1 to clear event status, write of 0 has no affect (access R/W1TC)
  [4] VE_EVENT — status/clear for verticle end. write 1 to clear event status, write of 0 has no affect (access R/W1TC)
  [3] VS_EVENT — status/clear for verticle start. write 1 to clear event status, write of 0 has no affect (access R/W1TC)
  [2] X_Y_EVENT — status/clear for x,y position match event. write 1 to clear event status, write of 0 has no affect (access R/W1TC)
  [1] X_Y_HALT — status/clear for x,y position match halt. write 1 to clear event status, write of 0 has no affect (access R/W1TC)
0x20C PAR_VPAC_VISS0__S_VBUSP__VISS_RAWFE__CFG__MMR__S_VBUSP__RAWFE_CFG_DBG_STAT2 ro
  [28:16] Y_POS — current y position
  [12:0] X_POS — current x position
0x210 PAR_VPAC_VISS0__S_VBUSP__VISS_RAWFE__CFG__MMR__S_VBUSP__RAWFE_CFG_DBG_STAT3 ro reset 0x90000000
  [31:2] DPC_MIRROR_STAT — dpc mirror status
  [1:0] DPC_LINE_RAM_CTL — ram control for understanding the phase of DPC line rams circular buffer for debug reads
0x214 PAR_VPAC_VISS0__S_VBUSP__VISS_RAWFE__CFG__MMR__S_VBUSP__RAWFE_CFG_DBG_STAT4 ro
  [31:0] LSC_DBG_STAT — lsc state machine
